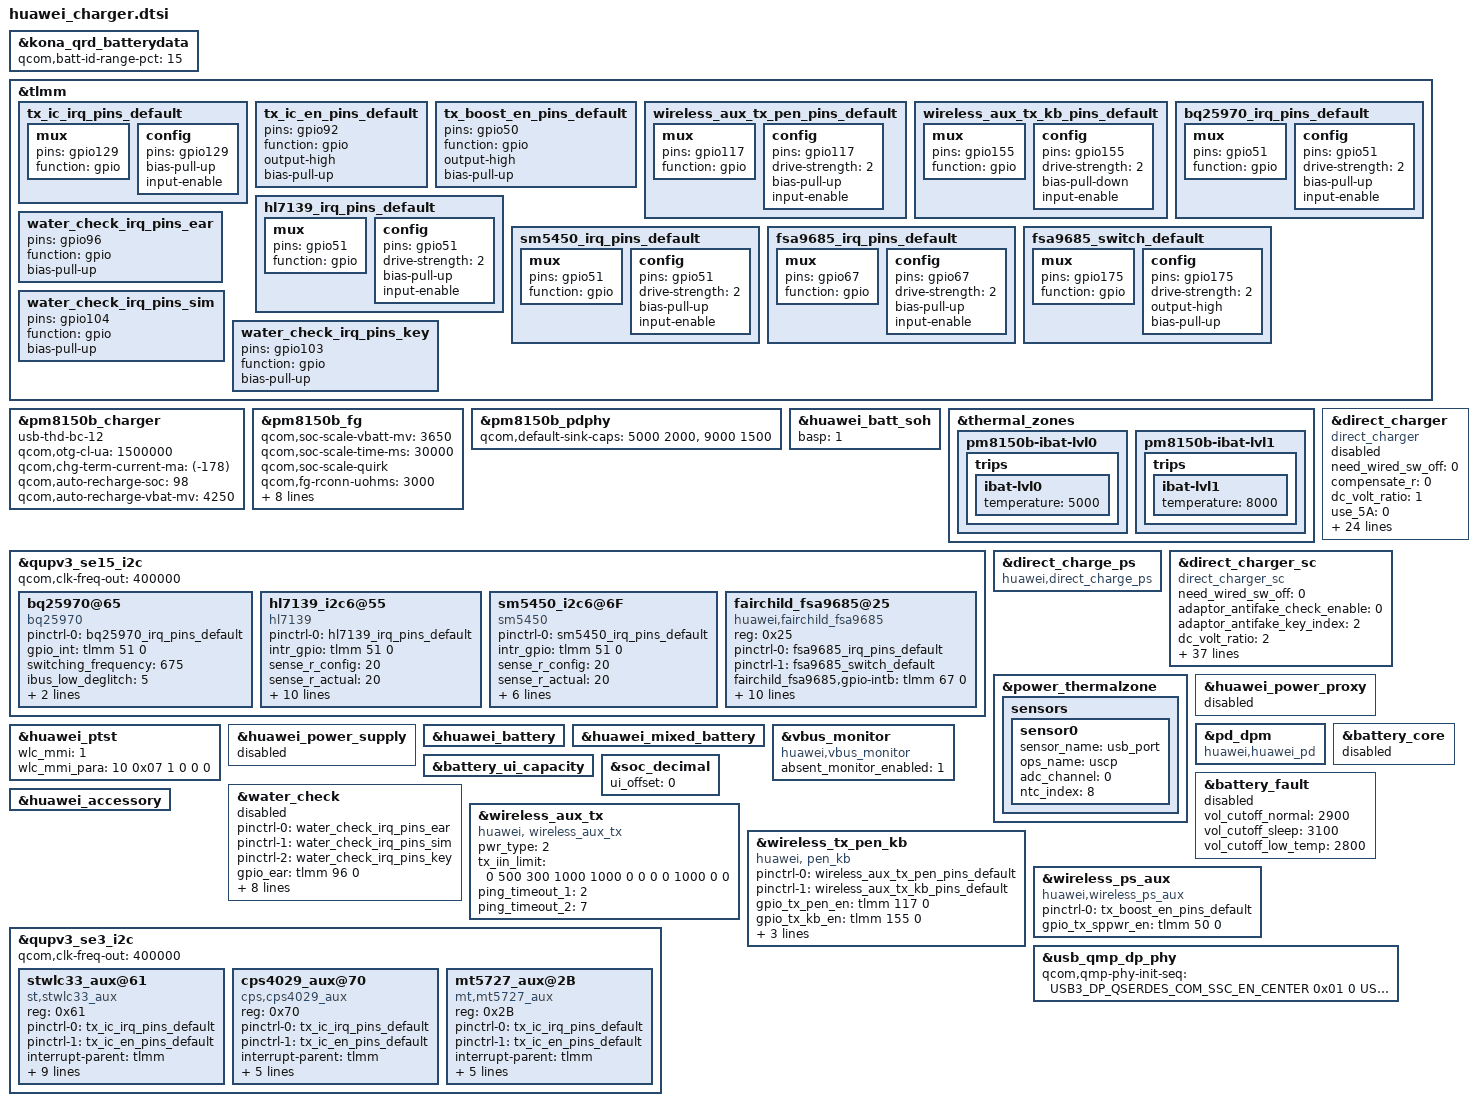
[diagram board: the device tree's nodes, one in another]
#include <dt-bindings/clock/qcom,gcc-kona.h>
#include <dt-bindings/phy/qcom,kona-qmp-usb3.h>

&kona_qrd_batterydata {
	qcom,batt-id-range-pct = <15>;
	#include "../../../huawei_charger/fg-gen4-batterydata-desayatl_7150_110k.dtsi"
	#include "../../../huawei_charger/fg-gen4-batterydata-sunwodacosmx_7150_200k.dtsi"
};

&tlmm {
	tx_ic_irq_pins_default: tx_ic_irq_pins_default {
		mux {
			pins = "gpio129";
			function = "gpio";
		};
		config {
			pins = "gpio129";
			bias-pull-up;
			input-enable;
		};
	};

	tx_ic_en_pins_default: tx_ic_en_pins_default {
		pins = "gpio92";
		function = "gpio";
		output-high;
		bias-pull-up;
	};

	tx_boost_en_pins_default: tx_boost_en_pins_default {
		pins = "gpio50";
		function = "gpio";
		output-high;
		bias-pull-up;
	};

	wireless_aux_tx_pen_pins_default: wireless_aux_tx_pen_pins_default {
		mux {
			pins = "gpio117";
			function = "gpio";
		};
		config {
			pins = "gpio117";
                        drive-strength = <2>;
                        bias-pull-up;
                        input-enable;
		};
	};

	wireless_aux_tx_kb_pins_default: wireless_aux_tx_kb_pins_default {
		mux {
			pins = "gpio155";
			function = "gpio";
		};
		config {
			pins = "gpio155";
			drive-strength = <2>;
			bias-pull-down;
			input-enable;
		};
	};

	bq25970_irq_pins_default: bq25970_irq_pins_default {
		mux {
			pins = "gpio51";
			function = "gpio";
		};
		config {
			pins = "gpio51";
			drive-strength = <2>;
			bias-pull-up;
			input-enable;
		};
	};

	hl7139_irq_pins_default: hl7139_irq_pins_default {
		mux {
			pins = "gpio51";
			function = "gpio";
		};
		config {
			pins = "gpio51";
			drive-strength = <2>;
			bias-pull-up;
			input-enable;
		};
	};

	sm5450_irq_pins_default: sm5450_irq_pins_default {
		mux {
			pins = "gpio51";
			function = "gpio";
		};
		config {
			pins = "gpio51";
			drive-strength = <2>;
			bias-pull-up;
			input-enable;
		};
	};

	fsa9685_irq_pins_default: fsa9685_irq_pins_default {
		mux {
			pins = "gpio67";
			function = "gpio";
		};
		config {
			pins = "gpio67";
			drive-strength = <2>;
			bias-pull-up;
			input-enable;
		};
	};

	fsa9685_switch_default: fsa9685_switch_default {
		mux {
			pins = "gpio175";
			function = "gpio";
		};
		config {
			pins = "gpio175";
			drive-strength = <2>;
			output-high;
			bias-pull-up;
		};
	};

	water_check_irq_pins_ear: water_check_irq_pins_ear {
		pins = "gpio96";
		function = "gpio";
		bias-pull-up;
	};
	water_check_irq_pins_sim: water_check_irq_pins_sim {
		pins = "gpio104";
		function = "gpio";
		bias-pull-up;
	};
	water_check_irq_pins_key: water_check_irq_pins_key {
		pins = "gpio103";
		function = "gpio";
		bias-pull-up;
	};

};

&pm8150b_charger {
	usb-thd-bc-12;
	qcom,otg-cl-ua = <1500000>;
	qcom,chg-term-current-ma = <(-178)>;
	qcom,auto-recharge-soc = <98>;
	qcom,auto-recharge-vbat-mv = <4250>;
};

&pm8150b_fg{
	qcom,soc-scale-vbatt-mv = <3650>;
	qcom,soc-scale-time-ms = <30000>;
	qcom,soc-scale-quirk;
	qcom,fg-rconn-uohms = <3000>;
	qcom,fg-cutoff-voltage = <3450>;
	qcom,slope-limit-temp-threshold = <100>;
	qcom,slope-limit-coeffs = <2500 2500 2500 500>;
	qcom,soc-hi-res;
	qcom,fg-sys-term-current = <(-600)>;
	io-channels = <&pm8150b_vadc ADC_BAT_THERM_PU1>;
	io-channel-names = "batt_therm";
	qcom,fg-temp-ir-for-current = <7500 55 6500 55 5500 55 4500 55 3500 50 2500 40 1500 30 500 20 0 10>;
};

&pm8150b_pdphy {
	qcom,default-sink-caps = <5000 2000>, /* 5V @ 2A */
				 <9000 1500>; /* 9V @ 2A */
};

&huawei_batt_soh {
	basp = <1>;
};

&thermal_zones {
	pm8150b-ibat-lvl0 {
		trips {
			ibat-lvl0 {
				temperature = <5000>;
			};
		};
	};

	pm8150b-ibat-lvl1 {
		trips {
			ibat-lvl1 {
				temperature = <8000>;
			};
		};
	};
};

&qupv3_se15_i2c {
	#address-cells = <1>;
	#size-cells = <0>;
	qcom,clk-freq-out = <400000>; /* if bq27z561_fg is used, i2c clock must be 100k(100000) */
	status = "ok";
	bq25970@65 {
		compatible = "bq25970";
		pinctrl-names = "default";
		pinctrl-0 = <&bq25970_irq_pins_default>;
		gpio_int = <&tlmm 51 0>;
		switching_frequency = <675>;
		ibus_low_deglitch = <5>;
		ucp_rise_threshold = <500>;
		reg = <0x65>;
		status = "ok";
	};

	hl7139_i2c6@55 {
		compatible = "hl7139";
		pinctrl-names = "default";
		pinctrl-0 = <&hl7139_irq_pins_default>;
		intr_gpio = <&tlmm 51 0>;
		sense_r_config = <20>;
		sense_r_actual = <20>;
		fcp_support = <1>;
		scp_support = <1>;
		check_irq_work_support = <1>;
		switching_frequency = <675>;
		vbat_ovp_para = <5000>;
		ibat_ocp_para = <6000>;
		vin_ovp_para = <11500>;
		iin_ocp_para = <3500>;
		sc_ibus_ocp = <3500>;
		reg = <0x55>;
		status = "ok";
	};

	sm5450_i2c6@6F {
		compatible = "sm5450";
		pinctrl-names = "default";
		pinctrl-0 = <&sm5450_irq_pins_default>;
		intr_gpio = <&tlmm 51 0>;
		sense_r_config = <20>;
		sense_r_actual = <20>;
		fcp_support = <1>;
		scp_support = <1>;
		sc_ibus_ocp = <3500>;
		check_irq_work_support = <1>;
		switching_frequency = <675>;
		reg = <0x6F>;
		status = "ok";
	};

	fairchild_fsa9685@25 {
		compatible = "huawei,fairchild_fsa9685";
		reg = <0x25>;
		pinctrl-names = "default", "switch_gpio_init";
		pinctrl-0 = <&fsa9685_irq_pins_default>;
		pinctrl-1 = <&fsa9685_switch_default>;
		fairchild_fsa9685,gpio-intb = <&tlmm 67 0>;
		switch_gpio = <&tlmm 175 0>;
		fcp_support = <1>;
		scp_support = <1>;
		need_other_bc12 = <0>;
		ignore_force_ac = <1>;
		/* for rt8979 */
		interrupt-names = "vbus_change", "device_change", "detach",
		              "attach";
		/* auto_switch; */
		scp;
		dcd;
		dcd_timeout = <600>;  /* ms */
		intb_watchdog = <1000>;  /* ms */
		ovp_sel = <14500000>;  /* uV */
		status = "ok";
	};
};

&direct_charge_ps {
	compatible = "huawei,direct_charge_ps";
	status = "ok";
};

&direct_charger{
	need_wired_sw_off = <0>;
	compensate_r = <0>;
	dc_volt_ratio = <1>;
	use_5A = <0>;
	scp_cable_detect_enable = <0>;
	max_adaptor_vset = <5500>;
	max_tadapt = <115>;
	max_tls = <115>;
	ibat_abnormal_th = <200>;
	first_cc_stage_timer_in_min = <0>;
	max_dc_bat_vol = <4350>;
	min_dc_bat_vol = <3550>;
	charge_control_interval = <5>;
	threshold_caculation_interval = <5>;
	safety_monitor_interval = <5>;
	scp_work_on_charger = <1>;
	init_adapter_vset = <4400>;
	init_delt_vset = <300>;
	vstep = <10>;
	delta_err = <200>;
	vol_err_th = <500>;
	full_path_res_max = <120>;
	standard_cable_full_path_res_max = <160>;
	max_current_for_none_standard_cable = <3000>;
	adaptor_leakage_current_th = <300>;
	stage_need_to_jump = "-1";
	temp_para =
		"-32767", "10", "0",
		"10", "45", "4750",
		"45", "32767", "0";
	compatible = "direct_charger";
	status = "disable";
};

&direct_charger_sc{
	compatible = "direct_charger_sc";
	need_wired_sw_off = <0>;
	adaptor_antifake_check_enable = <0>;
	adaptor_antifake_key_index = <2>;
	dc_volt_ratio = <2>;
	max_adaptor_vset = <11000>;
	max_tadapt = <115>;
	max_tls = <115>;
	ibat_abnormal_th = <200>;
	first_cc_stage_timer_in_min = <10>;
	max_dc_bat_vol = <4380>;
	min_dc_bat_vol = <3550>;
	charge_control_interval = <5>;
	threshold_caculation_interval = <5>;
	safety_monitor_interval = <5>;
	scp_work_on_charger = <1>;
	init_adapter_vset = <8800>;
	init_delt_vset = <450>;
	init_delt_iset = <1000>;
	vstep = <20>;
	delta_err = <300>;
	vol_err_th = <500>;
	full_path_res_max = <500>;
	standard_cable_full_path_res_max = <500>;
	max_current_for_none_standard_cable = <6000>;
	adaptor_leakage_current_th = <300>;
	stage_need_to_jump = "-1";
	compensate_r = <0>;
	cc_cable_detect_enable = <1>;
	cc_unsafe_sc_enable = <1>;
	is_show_ico_first = <1>;
	delta_err_10v2p25a = <150>;
	gain_curr_10v2a = <300>;
	volt_para =
		"4130", "5000", "4000",
		"4220", "5000", "4000",
		"4280", "4000", "2800",
		"4420", "2800", "1200";
	temp_para =
		"-32767", "10", "0",
		"10", "45", "5000",
		"45", "32767", "0";
	10v2p25a_cur_para =
		"-32767", "5500",  "2250",
		"5500",   "9000",  "2500",
		"9000",   "10000", "2250",
		"10000",  "10500", "2250",
		"10500",  "32767", "1500";
	resist_para =
		"0", "300", "6000",
		"300", "500", "4000";
	std_resist_para =
		"0", "300", "8200",
		"300", "500", "4000";
	status = "ok";
};

&power_thermalzone {
	status = "ok";
	sensors{
		sensor0 {
			sensor_name = "usb_port";
			ops_name = "uscp";
			adc_channel = <0>;
			ntc_index = <8>;
		};
	};
};

&huawei_power_proxy {
	status = "disabled";
};

&pd_dpm {
	compatible = "huawei,huawei_pd";
	status = "ok";
};

&huawei_ptst {
	wlc_mmi = <1>;
	wlc_mmi_para = <10 0x07 1 0 0 0>;
	status = "ok";
};

&huawei_power_supply {
	status = "disabled";
};

&huawei_battery {
	status = "ok";
};

&huawei_mixed_battery {
	status = "ok";
};

&battery_core {
	status = "disabled";
};

&vbus_monitor {
	compatible = "huawei,vbus_monitor";
	absent_monitor_enabled = <1>;
	status = "ok";
};

&battery_ui_capacity {
	status = "ok";
};

&soc_decimal {
	ui_offset = <0>;
	status = "ok";
};

&battery_fault {
	vol_cutoff_normal = <2900>;
	vol_cutoff_sleep = <3100>;
	vol_cutoff_low_temp = <2800>;
	status = "disabled";
};

&water_check {
	pinctrl-names = "water_check_irq_pins_ear",
			"water_check_irq_pins_sim",
			"water_check_irq_pins_key";
	pinctrl-0 = <&water_check_irq_pins_ear>;
	pinctrl-1 = <&water_check_irq_pins_sim>;
	pinctrl-2 = <&water_check_irq_pins_key>;
	gpio_ear = <&tlmm 96 0>; /* gpio_096 */
	gpio_sim = <&tlmm 104 0>; /* gpio_104 */
	gpio_key = <&tlmm 103 0>; /* gpio_103 */
	/* check_type, gpio_name, irq_no, multiple_handle, dmd_offset, prompt, action */
	water_check_para =
		"1", "ear", "-1", "1", "1", "0", "0",
		"1", "sim", "-1", "1", "2", "0", "0",
		"1", "key", "-1", "1", "3", "0", "0",
		"2", "null","-1", "0", "4", "0", "0",
		"3", "null","-1", "0", "5", "0", "0";
	irq_trigger_type = <1>; /* 1:low level trigger, 0:edge trigger */
	pinctrl_enable = <1>; /* 1:use pinctrl enable gpio pins state, 0:others */
	status = "disabled";
};

&wireless_aux_tx {
	compatible = "huawei, wireless_aux_tx";
	pwr_type = <2>; /* 0:VBUS_OTG 1:5VBST_OTG 2:SP-BST */
	tx_iin_limit = <0 500 300 1000 1000 0 0 0 0 1000 0 0>;
	ping_timeout_1 = <2>;
	ping_timeout_2 = <7>;
	status = "ok";
};

&wireless_tx_pen_kb {
	compatible = "huawei, pen_kb";
	pinctrl-names = "wireless_aux_tx_pen", "wireless_aux_tx_kb";
	pinctrl-0 = <&wireless_aux_tx_pen_pins_default>;
	pinctrl-1 = <&wireless_aux_tx_kb_pins_default>;
	gpio_tx_pen_en = <&tlmm 117 0>;
	gpio_tx_kb_en = <&tlmm 155 0>;
	support_pen_kb_switch = <1>;
	ping_timeout_pen = <2>;
	ping_timeout_kb = <30>;
	status = "ok";
};

&huawei_accessory {
	status = "ok";
};

&wireless_ps_aux {
	compatible = "huawei,wireless_ps_aux";
	pinctrl-names = "tx_boost_en_pins_default";
	pinctrl-0 = <&tx_boost_en_pins_default>;
	gpio_tx_sppwr_en = <&tlmm 50 0>;
	status = "ok";
};

&qupv3_se3_i2c {
	#address-cells = <1>;
	#size-cells = <0>;
	qcom,clk-freq-out = <400000>;
	status = "ok";
	stwlc33_aux@61 {
		compatible = "st,stwlc33_aux";
		reg = <0x61>;
		pinctrl-names = "stwwlc33_irq,stwlc33_en";
		pinctrl-0 = <&tx_ic_irq_pins_default>;
		pinctrl-1 = <&tx_ic_en_pins_default>;
		interrupt-parent = <&tlmm>;
		interrupts = <129 0>;
		gpio_int = <&tlmm 129 0>;
		gpio_en = <&tlmm 92 0>;
		gpio_en_valid_val = <0>;
		tx_fod_th_5v = <1500>;
		support_tx_adjust_vin = <1>;
		ping_freq_init_dym = <135>;
		tx_ploss_th0 = /bits/ 8 <0x19>; /* unit 100mW */
		tx_ploss_cnt = <3>;
		status = "ok";
	};

	cps4029_aux@70 {
		compatible = "cps,cps4029_aux";
		reg = <0x70>;
		pinctrl-names = "cps4029_irq,cps4029_en";
		pinctrl-0 = <&tx_ic_irq_pins_default>;
		pinctrl-1 = <&tx_ic_en_pins_default>;
		interrupt-parent = <&tlmm>;
		interrupts = <129 0>;
		gpio_int = <&tlmm 129 0>;
		gpio_en = <&tlmm 92 0>;
		tx_ploss_th0 = <2500>;
		tx_ploss_cnt = /bits/ 8 <0x4>;
		status = "ok";
	};
	mt5727_aux@2B {
		compatible = "mt,mt5727_aux";
		reg = <0x2B>;
		pinctrl-names = "mt5727_irq,mt5727_en";
		pinctrl-0 = <&tx_ic_irq_pins_default>;
		pinctrl-1 = <&tx_ic_en_pins_default>;
		interrupt-parent = <&tlmm>;
		interrupts = <129 0>;
		gpio_int = <&tlmm 129 0>;
		gpio_en = <&tlmm 92 0>;
		gpio_en_valid_val = <0>;
		tx_ping_ocp_th = <900>;
		status = "ok";
	};
};

&usb_qmp_dp_phy {
		qcom,qmp-phy-init-seq =
			/* <reg_offset, value, delay> */
			<USB3_DP_QSERDES_COM_SSC_EN_CENTER 0x01 0
			USB3_DP_QSERDES_COM_SSC_PER1 0x31 0
			USB3_DP_QSERDES_COM_SSC_PER2 0x01 0
			USB3_DP_QSERDES_COM_SSC_STEP_SIZE1_MODE0 0xDE 0
			USB3_DP_QSERDES_COM_SSC_STEP_SIZE2_MODE0 0x07 0
			USB3_DP_QSERDES_COM_SSC_STEP_SIZE1_MODE1 0xDE 0
			USB3_DP_QSERDES_COM_SSC_STEP_SIZE2_MODE1 0x07 0
			USB3_DP_QSERDES_COM_SYSCLK_BUF_ENABLE 0x0A 0
			USB3_DP_QSERDES_COM_CMN_IPTRIM 0x20 0
			USB3_DP_QSERDES_COM_CP_CTRL_MODE0 0x06 0
			USB3_DP_QSERDES_COM_CP_CTRL_MODE1 0x06 0
			USB3_DP_QSERDES_COM_PLL_RCTRL_MODE0 0x16 0
			USB3_DP_QSERDES_COM_PLL_RCTRL_MODE1 0x16 0
			USB3_DP_QSERDES_COM_PLL_CCTRL_MODE0 0x36 0
			USB3_DP_QSERDES_COM_PLL_CCTRL_MODE1 0x36 0
			USB3_DP_QSERDES_COM_SYSCLK_EN_SEL 0x1A 0
			USB3_DP_QSERDES_COM_LOCK_CMP_EN 0x04 0
			USB3_DP_QSERDES_COM_LOCK_CMP1_MODE0 0x14 0
			USB3_DP_QSERDES_COM_LOCK_CMP2_MODE0 0x34 0
			USB3_DP_QSERDES_COM_LOCK_CMP1_MODE1 0x34 0
			USB3_DP_QSERDES_COM_LOCK_CMP2_MODE1 0x82 0
			USB3_DP_QSERDES_COM_DEC_START_MODE0 0x82 0
			USB3_DP_QSERDES_COM_DEC_START_MODE1 0x82 0
			USB3_DP_QSERDES_COM_DIV_FRAC_START1_MODE0 0xAB 0
			USB3_DP_QSERDES_COM_DIV_FRAC_START2_MODE0 0xEA 0
			USB3_DP_QSERDES_COM_DIV_FRAC_START3_MODE0 0x02 0
			USB3_DP_QSERDES_COM_DIV_FRAC_START1_MODE1 0xAB 0
			USB3_DP_QSERDES_COM_DIV_FRAC_START2_MODE1 0xEA 0
			USB3_DP_QSERDES_COM_DIV_FRAC_START3_MODE1 0x02 0
			USB3_DP_QSERDES_COM_VCO_TUNE_MAP 0x02 0
			USB3_DP_QSERDES_COM_VCO_TUNE1_MODE0 0x24 0
			USB3_DP_QSERDES_COM_VCO_TUNE1_MODE1 0x24 0
			USB3_DP_QSERDES_COM_VCO_TUNE2_MODE1 0x02 0
			USB3_DP_QSERDES_COM_HSCLK_SEL 0x01 0
			USB3_DP_QSERDES_COM_CORECLK_DIV_MODE1 0x08 0
			USB3_DP_QSERDES_COM_BIN_VCOCAL_CMP_CODE1_MODE0 0xCA 0
			USB3_DP_QSERDES_COM_BIN_VCOCAL_CMP_CODE2_MODE0 0x1E 0
			USB3_DP_QSERDES_COM_BIN_VCOCAL_CMP_CODE1_MODE1 0xCA 0
			USB3_DP_QSERDES_COM_BIN_VCOCAL_CMP_CODE2_MODE1 0x1E 0
			USB3_DP_QSERDES_COM_BIN_VCOCAL_HSCLK_SEL 0x11 0
			USB3_DP_QSERDES_TXA_RES_CODE_LANE_TX 0x60 0
			USB3_DP_QSERDES_TXA_RES_CODE_LANE_RX 0x60 0
			USB3_DP_QSERDES_TXA_RES_CODE_LANE_OFFSET_TX 0x11 0
			USB3_DP_QSERDES_TXA_RES_CODE_LANE_OFFSET_RX 0x02 0
			USB3_DP_QSERDES_TXA_TX_EMP_POST1_LVL 0x3C 0
			USB3_DP_QSERDES_TXA_TX_DRV_LVL 0x3F 0
			USB3_DP_QSERDES_TXA_LANE_MODE_1 0xD5 0
			USB3_DP_QSERDES_TXA_LANE_MODE_2 0x00 0
			USB3_DP_QSERDES_TXA_RCV_DETECT_LVL_2 0x12 0
			USB3_DP_QSERDES_TXA_PI_QEC_CTRL 0x40 0
			USB3_DP_QSERDES_RXA_UCDR_FO_GAIN 0x09 0
			USB3_DP_QSERDES_RXA_UCDR_SO_GAIN 0x05 0
			USB3_DP_QSERDES_RXA_UCDR_FASTLOCK_FO_GAIN 0x2F 0
			USB3_DP_QSERDES_RXA_UCDR_SO_SATURATION_AND_ENABLE 0x7F 0
			USB3_DP_QSERDES_RXA_UCDR_FASTLOCK_COUNT_LOW 0xFF 0
			USB3_DP_QSERDES_RXA_UCDR_FASTLOCK_COUNT_HIGH 0x0F 0
			USB3_DP_QSERDES_RXA_UCDR_PI_CONTROLS 0x99 0
			USB3_DP_QSERDES_RXA_UCDR_SB2_THRESH1 0x08 0
			USB3_DP_QSERDES_RXA_UCDR_SB2_THRESH2 0x08 0
			USB3_DP_QSERDES_RXA_UCDR_SB2_GAIN1 0x00 0
			USB3_DP_QSERDES_RXA_UCDR_SB2_GAIN2 0x04 0
			USB3_DP_QSERDES_RXA_VGA_CAL_CNTRL1 0x54 0
			USB3_DP_QSERDES_RXA_VGA_CAL_CNTRL2 0x0C 0
			USB3_DP_QSERDES_RXA_RX_EQU_ADAPTOR_CNTRL2 0x0F 0
			USB3_DP_QSERDES_RXA_RX_EQU_ADAPTOR_CNTRL3 0x4A 0
			USB3_DP_QSERDES_RXA_RX_EQU_ADAPTOR_CNTRL4 0x0A 0
			USB3_DP_QSERDES_RXA_RX_IDAC_TSETTLE_LOW 0xC0 0
			USB3_DP_QSERDES_RXA_RX_IDAC_TSETTLE_HIGH 0x00 0
			USB3_DP_QSERDES_RXA_RX_EQ_OFFSET_ADAPTOR_CNTRL1 0x77 0
			USB3_DP_QSERDES_RXA_SIGDET_CNTRL 0x04 0
			USB3_DP_QSERDES_RXA_SIGDET_DEGLITCH_CNTRL 0x0E 0
			USB3_DP_QSERDES_RXA_RX_MODE_00_LOW 0xFF 0
			USB3_DP_QSERDES_RXA_RX_MODE_00_HIGH 0x7F 0
			USB3_DP_QSERDES_RXA_RX_MODE_00_HIGH2 0x7F 0
			USB3_DP_QSERDES_RXA_RX_MODE_00_HIGH3 0x7F 0
			USB3_DP_QSERDES_RXA_RX_MODE_00_HIGH4 0x97 0
			USB3_DP_QSERDES_RXA_RX_MODE_01_LOW 0xDC 0
			USB3_DP_QSERDES_RXA_RX_MODE_01_HIGH 0xDC 0
			USB3_DP_QSERDES_RXA_RX_MODE_01_HIGH2 0x5C 0
			USB3_DP_QSERDES_RXA_RX_MODE_01_HIGH3 0x7B 0
			USB3_DP_QSERDES_RXA_RX_MODE_01_HIGH4 0xB4 0
			USB3_DP_QSERDES_RXA_DFE_EN_TIMER 0x04 0
			USB3_DP_QSERDES_RXA_DFE_CTLE_POST_CAL_OFFSET 0x38 0
			USB3_DP_QSERDES_RXA_AUX_DATA_TCOARSE_TFINE 0xA0 0
			USB3_DP_QSERDES_RXA_DCC_CTRL1 0x0C 0
			USB3_DP_QSERDES_RXA_GM_CAL 0x1F 0
			USB3_DP_QSERDES_RXA_VTH_CODE 0x10 0
			USB3_DP_QSERDES_TXB_RES_CODE_LANE_TX 0x60 0
			USB3_DP_QSERDES_TXB_RES_CODE_LANE_RX 0x60 0
			USB3_DP_QSERDES_TXB_RES_CODE_LANE_OFFSET_TX 0x11 0
			USB3_DP_QSERDES_TXB_RES_CODE_LANE_OFFSET_RX 0x02 0
			USB3_DP_QSERDES_TXB_TX_EMP_POST1_LVL 0x3C 0
			USB3_DP_QSERDES_TXB_TX_DRV_LVL 0x3F 0
			USB3_DP_QSERDES_TXB_LANE_MODE_1 0xD5 0
			USB3_DP_QSERDES_TXB_LANE_MODE_2 0x00 0
			USB3_DP_QSERDES_TXB_RCV_DETECT_LVL_2 0x12 0
			USB3_DP_QSERDES_TXB_PI_QEC_CTRL 0x54 0
			USB3_DP_QSERDES_RXB_UCDR_FO_GAIN 0x09 0
			USB3_DP_QSERDES_RXB_UCDR_SO_GAIN 0x05 0
			USB3_DP_QSERDES_RXB_UCDR_FASTLOCK_FO_GAIN 0x2F 0
			USB3_DP_QSERDES_RXB_UCDR_SO_SATURATION_AND_ENABLE 0x7F 0
			USB3_DP_QSERDES_RXB_UCDR_FASTLOCK_COUNT_LOW 0xFF 0
			USB3_DP_QSERDES_RXB_UCDR_FASTLOCK_COUNT_HIGH 0x0F 0
			USB3_DP_QSERDES_RXB_UCDR_PI_CONTROLS 0x99 0
			USB3_DP_QSERDES_RXB_UCDR_SB2_THRESH1 0x08 0
			USB3_DP_QSERDES_RXB_UCDR_SB2_THRESH2 0x08 0
			USB3_DP_QSERDES_RXB_UCDR_SB2_GAIN1 0x00 0
			USB3_DP_QSERDES_RXB_UCDR_SB2_GAIN2 0x04 0
			USB3_DP_QSERDES_RXB_VGA_CAL_CNTRL1 0x54 0
			USB3_DP_QSERDES_RXB_VGA_CAL_CNTRL2 0x0C 0
			USB3_DP_QSERDES_RXB_RX_EQU_ADAPTOR_CNTRL2 0x0F 0
			USB3_DP_QSERDES_RXB_RX_EQU_ADAPTOR_CNTRL3 0x4A 0
			USB3_DP_QSERDES_RXB_RX_EQU_ADAPTOR_CNTRL4 0x0A 0
			USB3_DP_QSERDES_RXB_RX_IDAC_TSETTLE_LOW 0xC0 0
			USB3_DP_QSERDES_RXB_RX_IDAC_TSETTLE_HIGH 0x00 0
			USB3_DP_QSERDES_RXB_RX_EQ_OFFSET_ADAPTOR_CNTRL1 0x77 0
			USB3_DP_QSERDES_RXB_SIGDET_CNTRL 0x04 0
			USB3_DP_QSERDES_RXB_SIGDET_DEGLITCH_CNTRL 0x0E 0
			USB3_DP_QSERDES_RXB_RX_MODE_00_LOW 0x7F 0
			USB3_DP_QSERDES_RXB_RX_MODE_00_HIGH 0xFF 0
			USB3_DP_QSERDES_RXB_RX_MODE_00_HIGH2 0x3F 0
			USB3_DP_QSERDES_RXB_RX_MODE_00_HIGH3 0x7F 0
			USB3_DP_QSERDES_RXB_RX_MODE_00_HIGH4 0xA6 0
			USB3_DP_QSERDES_RXB_RX_MODE_01_LOW 0xDC 0
			USB3_DP_QSERDES_RXB_RX_MODE_01_HIGH 0xDC 0
			USB3_DP_QSERDES_RXB_RX_MODE_01_HIGH2 0x5C 0
			USB3_DP_QSERDES_RXB_RX_MODE_01_HIGH3 0x7B 0
			USB3_DP_QSERDES_RXB_RX_MODE_01_HIGH4 0xB4 0
			USB3_DP_QSERDES_RXB_DFE_EN_TIMER 0x04 0
			USB3_DP_QSERDES_RXB_DFE_CTLE_POST_CAL_OFFSET 0x38 0
			USB3_DP_QSERDES_RXB_AUX_DATA_TCOARSE_TFINE 0xA0 0
			USB3_DP_QSERDES_RXB_DCC_CTRL1 0x0C 0
			USB3_DP_QSERDES_RXB_GM_CAL 0x1F 0
			USB3_DP_QSERDES_RXB_VTH_CODE 0x10 0
			USB3_DP_PCS_G12S1_TXMGN_V0 0x3F 0
			USB3_DP_PCS_G12S1_TXDEEMPH_M6DB 0x3C 0
			USB3_DP_PCS_G12S1_TXDEEMPH_M3P5DB 0x3C 0
			USB3_DP_PCS_LOCK_DETECT_CONFIG1 0xD0 0
			USB3_DP_PCS_LOCK_DETECT_CONFIG2 0x07 0
			USB3_DP_PCS_LOCK_DETECT_CONFIG3 0x20 0
			USB3_DP_PCS_LOCK_DETECT_CONFIG6 0x13 0
			USB3_DP_PCS_REFGEN_REQ_CONFIG1 0x21 0
			USB3_DP_PCS_RX_SIGDET_LVL 0xA9 0
			USB3_DP_PCS_CDR_RESET_TIME 0x0A 0
			USB3_DP_PCS_ALIGN_DETECT_CONFIG1 0x88 0
			USB3_DP_PCS_ALIGN_DETECT_CONFIG2 0x13 0
			USB3_DP_PCS_PCS_TX_RX_CONFIG 0x0C 0
			USB3_DP_PCS_EQ_CONFIG1 0x4B 0
			USB3_DP_PCS_EQ_CONFIG5 0x10 0
			USB3_DP_PCS_USB3_LFPS_DET_HIGH_COUNT_VAL 0xF8 0
			USB3_DP_PCS_USB3_RXEQTRAINING_DFE_TIME_S2 0x07 0
			0xffffffff 0xffffffff 0x00>;
};
